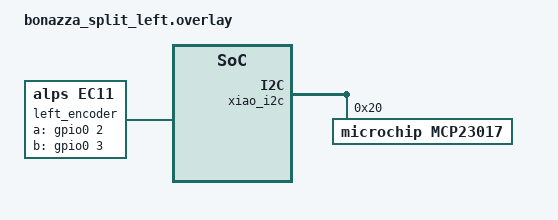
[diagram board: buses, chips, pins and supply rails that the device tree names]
#include "bonazza_split.dtsi"

&xiao_i2c {
    status = "okay";
    mcp23017: mcp23017@20 {
        compatible = "microchip,mcp23017";
        reg = <0x20>;
        gpio-controller;
        #gpio-cells = <2>;
        ngpios = <16>;
    };
};

/ {
    left_encoder: encoder_left {
        compatible = "alps,ec11";
        a-gpios = <&gpio0 2 (GPIO_ACTIVE_HIGH | GPIO_PULL_UP)>;
        b-gpios = <&gpio0 3 (GPIO_ACTIVE_HIGH | GPIO_PULL_UP)>;
        steps = <80>;
        status = "okay";
    };

    sensors: sensors {
        compatible = "zmk,keymap-sensors";
        sensors = <&left_encoder>;
        triggers-per-rotation = <20>;
    };
};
